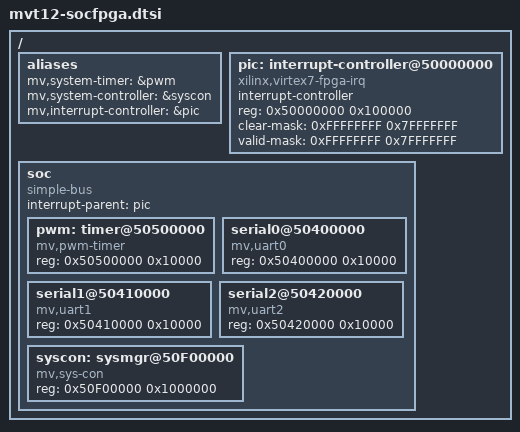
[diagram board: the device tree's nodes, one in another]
/*
 *  Copyright (C) 2015 Mtekvision Corporation <www.mtekvision.com>
 *
 * This program is free software; you can redistribute it and/or modify
 * it under the terms of the GNU General Public License as published by
 * the Free Software Foundation; either version 2 of the License, or
 * (at your option) any later version.
 *
 * This program is distributed in the hope that it will be useful,
 * but WITHOUT ANY WARRANTY; without even the implied warranty of
 * MERCHANTABILITY or FITNESS FOR A PARTICULAR PURPOSE.  See the
 * GNU General Public License for more details.
 *
 * You should have received a copy of the GNU General Public License
 * along with this program.  If not, see <http://www.gnu.org/licenses/>.
 *
 * --------------------------------------------------------------------
 * Device Tree Source for MV89XX SoC
 * --------------------------------------------------------------------
 */

/include/ "skeleton.dtsi"

/ {
	#address-cells = <1>;
	#size-cells = <1>;

	aliases {
		mv,system-timer = &pwm;
		mv,system-controller = &syscon;
		mv,interrupt-controller = &pic;
	};

	pic: interrupt-controller@50000000 {
		compatible = "xilinx,virtex7-fpga-irq";
		#interrupt-cells = <1>;
		interrupt-controller;
		reg = <0x50000000 0x100000>;
		clear-mask = <0xFFFFFFFF 0x7FFFFFFF>;
		valid-mask = <0xFFFFFFFF 0x7FFFFFFF>;
	};

	soc {
		compatible = "simple-bus";
		device_type = "soc";
		#address-cells = <1>;
		#size-cells = <1>;
		interrupt-parent = <&pic>;
		ranges;

		pwm: timer@50500000 {
			compatible = "mv,pwm-timer";
			reg = <0x50500000 0x10000>;
		};

		serial0@50400000 {
			compatible = "mv,uart0";
			reg = <0x50400000 0x10000>;
		};

		serial1@50410000 {
			compatible = "mv,uart1";
			reg = <0x50410000 0x10000>;
		};

		serial2@50420000 {
			compatible = "mv,uart2";
			reg = <0x50420000 0x10000>;
		};

		syscon: sysmgr@50F00000 {
			compatible = "mv,sys-con";
			reg = <0x50F00000 0x1000000>;
		};
	};
};

/include/ "mvt12-video-processor.dtsi"
/include/ "mvt12-css.dtsi"
